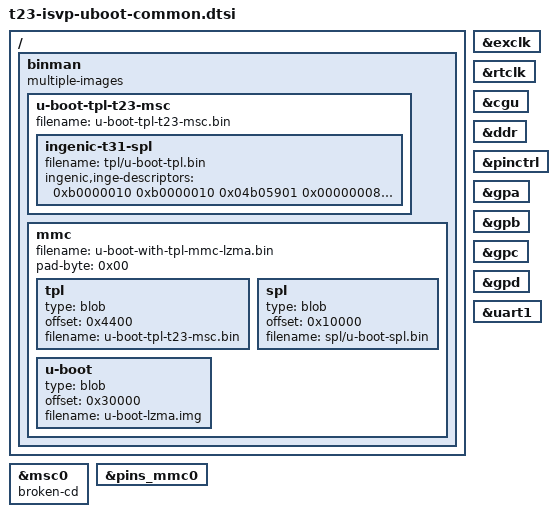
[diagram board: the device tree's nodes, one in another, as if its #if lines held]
// SPDX-License-Identifier: GPL-2.0+
/*
 * Shared U-Boot overlay for the Ingenic ISVP-T23 SFC-NOR leaf DTs.
 * Each per-SKU <leaf>-u-boot.dtsi is a one-line #include of this file
 * (the U-Boot build auto-appends <leaf>-u-boot.dtsi to <leaf>.dts).
 *
 * T23 boots a TPL chain. Its mask ROM loads the whole first-stage image, but
 * the bootrom's cache-as-RAM lock window (~0xe000) cannot hold the SPL once it
 * carries the DM + SFC/MMC stack - so, like the capped XBurst1 SoCs, the
 * bring-up is split: the ROM loads the headered TPL at offset 0; the TPL brings
 * up DDR in cache-as-RAM and reads the DRAM-resident SPL from 0x8000; the SPL
 * reads U-Boot from 0x18000 (= CONFIG_SYS_SPI_U_BOOT_OFFS). The 2 KiB header
 * CRC7+length is finalized by the family-generic ingenic-t31-spl binman etype.
 *
 * Phase tags: the TPL/SPL devicetrees are fdtgrep-filtered out of the single
 * dt.dtb by bootph tags (TPL keeps bootph-all + bootph-pre-sram; SPL keeps
 * bootph-all + bootph-pre-ram), NOT re-preprocessed per phase. The TPL's only
 * DM device is &ddr (its probe brings up PLL + DDR, then it hand-loads the SPL
 * with bare-metal SFC/serial helpers), so only &ddr is tagged for all phases;
 * every other node is bootph-pre-ram + bootph-some-ram (present in the SPL DM
 * NOR boot and U-Boot pre-reloc, absent from the minimal TPL).
 */

/ {
	binman: binman {
		multiple-images;
	};
};

&binman {
#if defined(CONFIG_SPL_MMC)
	/*
	 * MSC/SD-card boot image (isvp_t23_msc0). The XBurst1 SD ROM
	 * (msc_sd_boot -> FUN_bfc032d0) parses an INGE block at the first
	 * stage's +0x100 to program APLL/MPLL/CPCCR + MSC0CDR (the SD read
	 * clock) and learn the load size before the heavy read - there is no
	 * usable default, unlike the XBurst2 T40/T41 ROM. With a TPL chain the
	 * first stage the ROM reads is the TPL, so the INGE rides on the TPL
	 * here (vendor T23 table from spl_params_fixer.c CONFIG_T23: APLL 600M,
	 * MPLL 1200M, CPCCR, MSC0CDR -> 24 MHz; the etype appends the
	 * 0xffffffff terminator). SD layout: TPL at sector 34 (0x4400), the
	 * DRAM-resident SPL at 0x10000 (the TPL reads it bare-metal), U-Boot at
	 * SYS_MMCSD_RAW_MODE_U_BOOT_SECTOR (0x180 = byte 0x30000).
	 */
	u-boot-tpl-t23-msc {
		filename = "u-boot-tpl-t23-msc.bin";

		ingenic-t31-spl {
			filename = "tpl/u-boot-tpl.bin";
			ingenic,inge-descriptors = <
				0xb0000010 0xb0000010 0x04b05901 0x00000008 0x00000000
				0xb0000014 0xb0000014 0x06405101 0x00000008 0x00000000
				0xb0000000 0xb00000d4 0x95773310 0x00000000 0x00000007
				0xb0000000 0xffffffff 0x9a7b5510 0x00000000 0x00000000
				0xb0000068 0xb0000068 0x60000018 0x00000000 0x10000000>;
		};
	};

	mmc {
		filename = "u-boot-with-tpl-mmc-lzma.bin";
		pad-byte = <0x00>;

		tpl {
			type = "blob";
			offset = <0x4400>;
			filename = "u-boot-tpl-t23-msc.bin";
		};

		spl {
			type = "blob";
			offset = <0x10000>;
			filename = "spl/u-boot-spl.bin";
		};

		u-boot {
			type = "blob";
			offset = <0x30000>;
			filename = "u-boot-lzma.img";
		};
	};
#elif defined(CONFIG_TPL)
	u-boot-tpl-t23 {
		filename = "u-boot-tpl-t23.bin";

		ingenic-t31-spl {
			filename = "tpl/u-boot-tpl.bin";
		};
	};

	flash {
		filename = "u-boot-with-tpl-lzma.bin";
		pad-byte = <0xff>;

		tpl {
			type = "blob";
			offset = <0x0>;
			filename = "u-boot-tpl-t23.bin";
		};

		spl {
			type = "blob";
			offset = <0x8000>;
			filename = "spl/u-boot-spl.bin";
		};

		u-boot {
			type = "blob";
			offset = <0x18000>;
			filename = "u-boot-lzma.img";
		};
	};
#else
	u-boot-spl-t23 {
		filename = "u-boot-spl-t23.bin";

		ingenic-t31-spl {
			filename = "spl/u-boot-spl.bin";
		};
	};

	flash {
		filename = "u-boot-with-spl-lzma.bin";
		pad-byte = <0xff>;

		spl {
			type = "blob";
			offset = <0x0>;
			filename = "u-boot-spl-t23.bin";
		};

		u-boot {
			type = "blob";
			offset = <0x14000>;
			filename = "u-boot-lzma.img";
		};
	};
#endif
};

&exclk { bootph-pre-ram; bootph-some-ram; };
&rtclk { bootph-pre-ram; bootph-some-ram; };
&cgu { bootph-pre-ram; bootph-some-ram; };
&ddr { bootph-all; };		/* the TPL's only DM device */
&pinctrl { bootph-pre-ram; bootph-some-ram; };
&gpa { bootph-pre-ram; bootph-some-ram; };
&gpb { bootph-pre-ram; bootph-some-ram; };
&gpc { bootph-pre-ram; bootph-some-ram; };
&gpd { bootph-pre-ram; bootph-some-ram; };
&uart1 { bootph-pre-ram; bootph-some-ram; };

#if defined(CONFIG_SPL_MMC)
/*
 * MSC/SD boot: the SPL probes the native jz_mmc controller (the TPL's SD
 * read is bare-metal, so the TPL devicetree still needs only &ddr). msc0 is
 * status="disabled" in t23.dtsi - the NOR boards never use it - so enable it
 * here and tag it + its pins for the SPL and pre-reloc U-Boot phases.
 */
&msc0 {
	bootph-pre-ram;
	bootph-some-ram;
	broken-cd;		/* the SD is the boot medium - always present */
	status = "okay";
};
&pins_mmc0 { bootph-pre-ram; bootph-some-ram; };
#else
&pins_sfc { bootph-pre-ram; bootph-some-ram; };
&sfc {
	bootph-pre-ram;
	bootph-some-ram;
	flash@0 {
		bootph-pre-ram;
		bootph-some-ram;
	};
};
#endif
